# SAM9X75D2GN4 device description
Architecture: ARM926EJ-S; Family: SAM9; Series: SAM9X7
Registers are 32-bit, read-write, reset 0x0 unless marked. A register's access mark holds for its fields unless they carry their own. Offsets are from the block's base; [hi:lo] are bit positions; lines under a group give offsets from that group; {n}, {i} and the like mark numbered series; 'fields as' and 'values as' point back to an identical list.

## GMAC (part 1 of 3) — Gigabit Ethernet MAC
Instances: GMAC 0xF802C000
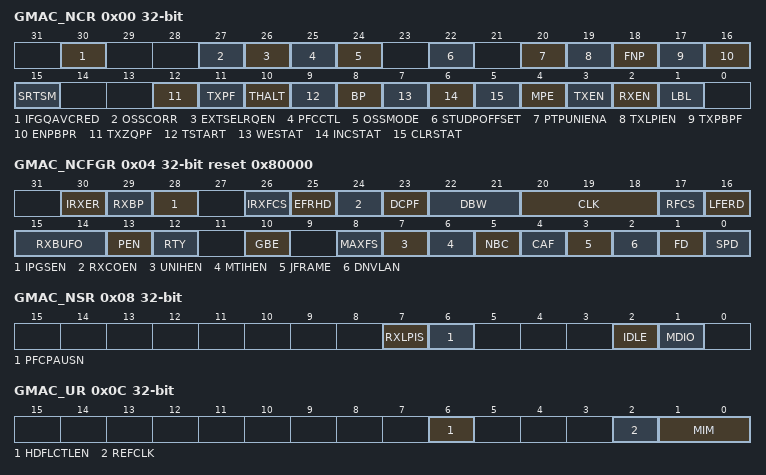
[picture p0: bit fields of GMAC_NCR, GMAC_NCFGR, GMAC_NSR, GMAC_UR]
0x00 GMAC_NCR — Network Control Register
  [30] IFGQAVCRED — Credit-Based Shaping Algorithm Modification
    0=No modification of the CBS algorithm; 1=Modifies the CBS algorithm so the IFG/IPG associated with a transmit frame counts towards its 802.1Qav credit
  [27] OSSCORR — OSS Correction Field
  [26] EXTSELRQEN — External Selection of Receive Queue Enable
    0=Disables external selection of receive queue; 1=Enables external selection of receive queue
  [25] PFCCTL — Multiple PFC Pause quantum Enable
    0=Disables multiple PFC pause quantums; 1=Enables multiple PFC pause quantums, one per pause priority
  [24] OSSMODE — One Step Sync Mode
    0=1588 One Step Sync Mode is disabled; 1=1588 One Step Sync Mode is enabled. Replaces timestamp field in the 1588 header for TX Sync Frames with the current TSU timer value.
  [22] STUDPOFFSET — Store UDP Offset
    0=Normal operations; 1=The upper 16 bits of the CRC of every received frame are replaced with the offset from start of frame to the beginning of the UDP or TCP header. The lower 16 bits of the CRC are replaced with zero and reserved for future use. The offset is measured in units of 2 bytes.
  [20] PTPUNIENA — Detection of Unicast PTP Frames Enable
    0=Disables detection of unicast PTP frames; 1=Enables detection of unicast PTP frames
  [19] TXLPIEN — Enable LPI Transmission
  [18] FNP — Flush Next Packet
    0=No effect; 1=Flushes the next packet from the receive memory. This will only have an effect if the DMA is not currently writing a packet already stored in the receive memory to system memory.
  [17] TXPBPF — Transmit PFC Priority-based Pause Frame
    0=No effect; 1=Takes the values stored in the Transmit PFC Pause Register
  [16] ENPBPR — Enable PFC Priority-based Pause Reception
  [15] SRTSM — Store Receive Timestamp to Memory
    0=No effect; 1=Causes the CRC of every received frame to be replaced with the value of the nanoseconds field of the 1588 timer that was captured as the receive frame passed the message timestamp point. Note that bit RFCS in register GMAC_NCFGR may not be set to 1 when the timer should be captured.
  [12] TXZQPF — Transmit Zero Quantum Pause Frame (Write-only)
    0=No effect; 1=Generates a pause frame with zero quantum to be transmitted
  [11] TXPF — Transmit Pause Frame (Write-only)
    0=No effect; 1=Generates a pause frame to be transmitted
  [10] THALT — Transmit Halt (Write-only)
    0=No effect; 1=Halts transmission as soon as any ongoing frame transmission ends
  [9] TSTART — Start Transmission (Write-only)
    0=No effect; 1=Starts transmission
  [8] BP — Back Pressure
    0=No effect; 1=When the MAC is set in 10M or 100M Half Duplex mode, forces collisions on all received frames. Ignored in Gigabit Half Duplex mode.
  [7] WESTAT — Write Enable for Statistics Registers
    0=Forces the statistics registers to be in read-only mode for normal operation mode; 1=Makes the statistics registers writable for functional test purposes
  [6] INCSTAT — Increment Statistics Registers (Write-only)
  [5] CLRSTAT — Clear Statistics Registers (Write-only)
    0=No effect; 1=Clears the statistics registers
  [4] MPE — Management Port Enable
    0=Forces GMDIO to high impedance state and MDC low; 1=Enables the management port
  [3] TXEN — Transmit Enable
    0=Stops transmission immediately, the transmit pipeline and control registers will be cleared and the Transmit Queue Pointer Register will reset to point to the start of the transmit descriptor list; 1=Enables the GMAC transmitter to send data
  [2] RXEN — Receive Enable
    0=Stops frame reception immediately and the receive pipeline will be cleared. The Receive Queue Pointer register is unaffected.; 1=Enables the GMAC to receive data
  [1] LBL — Loop Back Local
    0=Normal operating mode (no loop back); 1=Connects GTX to GRX, GTXEN to GRXDV and forces Full Duplex mode. GRXCK and GTXCK may malfunction as the GMAC is switched into and out of internal loop back. It is important that receive and transmit circuits have already been disabled when making the switch into and out of internal loop back.
0x04 GMAC_NCFGR reset 0x80000 — Network Configuration Register
  [30] IRXER — Ignore Receive Error from PHY
  [29] RXBP — Receive Bad Preamble
  [28] IPGSEN — IP Stretch Enable
  [26] IRXFCS — Ignore RX FCS
  [25] EFRHD — Enable Frames Received in Half Duplex
  [24] RXCOEN — Receive Checksum Offload Enable
  [23] DCPF — Disable Copy of Pause Frames
  [22:21] DBW — Data Bus Width
  [20:18] CLK — MDC CLock Division
    0=MCK_8 (MCK divided by 8 (MCK up to 20 MHz)); 1=MCK_16 (MCK divided by 16 (MCK up to 40 MHz)); 2=MCK_32 (MCK divided by 32 (MCK up to 80 MHz)); 3=MCK_48 (MCK divided by 48 (MCK up to 120 MHz)); 4=MCK_64 (MCK divided by 64 (MCK up to 160 MHz)); 5=MCK_96 (MCK divided by 96 (MCK up to 240 MHz))
  [17] RFCS — Remove FCS
  [16] LFERD — Length Field Error Frame Discard
  [15:14] RXBUFO — Receive Buffer Offset
  [13] PEN — Pause Enable
  [12] RTY — Retry Test0
  [10] GBE — Gigabit Mode Enable
    0=10/100 operation; 1=Gigabit operation
  [8] MAXFS — 1536 Maximum Frame Size
  [7] UNIHEN — Unicast Hash Enable
  [6] MTIHEN — Multicast Hash Enable
  [5] NBC — No Broadcast
  [4] CAF — Copy All Frames
  [3] JFRAME — Jumbo Frame Size
  [2] DNVLAN — Discard Non-VLAN FRAMES
  [1] FD — Full Duplex
  [0] SPD — Speed
0x08 GMAC_NSR ro reset not defined — Network Status Register
  [7] RXLPIS — LPI Indication
  [6] PFCPAUSN — PFC Pause Negotiated
  [2] IDLE — PHY Management Logic Idle
  [1] MDIO — MDIO Input Status
0x0C GMAC_UR — User Register
  [6] HDFLCTLEN — Half Duplex Flow Control Enable
    0=Half duplex flow control is disabled; 1=Half duplex flow control is enabled
  [2] REFCLK — Source for the GMAC Reference Clock
    0=INTERNAL_GCLK (Selects the GCLK from PMC); 1=EXTERNAL (Selects the clock from an IO)
  [1:0] MIM — Media Interface Mode
    1=RMII (Selects the RMII mode.); 2=RGMII (Selects the RGMII mode.)
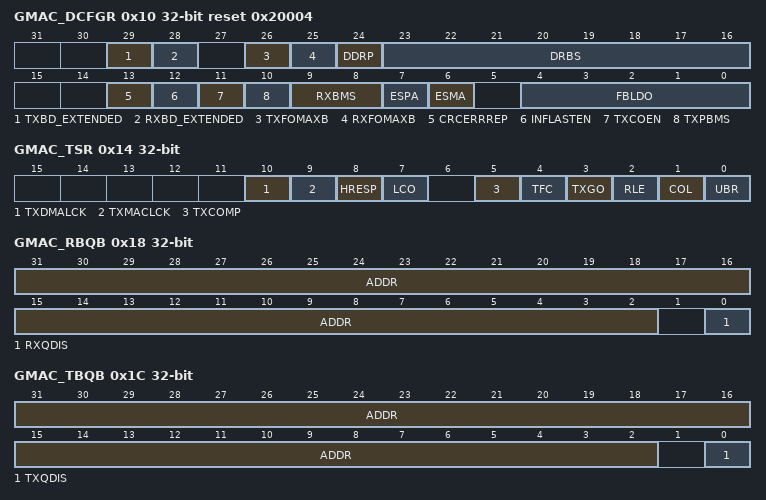
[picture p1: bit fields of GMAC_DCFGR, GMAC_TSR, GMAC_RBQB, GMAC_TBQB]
0x10 GMAC_DCFGR reset 0x20004 — DMA Configuration Register
  [29] TXBD_EXTENDED — Transmit Buffer Descriptor Extended Mode
    0=Disables Transmit Buffer Data Extended mode; 1=Enables Transmit Buffer Data Extended mode
  [28] RXBD_EXTENDED — Receive Buffer Descriptor Extended Mode
    0=Disables Receive Buffer Data Extended mode; 1=Enables Receive Buffer Data Extended mode
  [26] TXFOMAXB — Force Transmit Max Burst Length
  [25] RXFOMAXB — Force Receive Max Burst Length
  [24] DDRP — DMA Discard Receive Packets
  [23:16] DRBS — DMA Receive Buffer Size
    2=128 bytes; 24=1536 bytes (1 x max length frame/buffer); 160=10240 bytes (1 x 10K jumbo frame/buffer)
  [13] CRCERRREP — CRC Errors Report
    0=Bit 16 of the receive buffer descriptor represents the Canonical format indicator (CFI) bit as extracted from the receive frame (if the receive buffer descriptor is pointing to the last data buffer of the receive frame and the received frame was VLAN tagged); 1=Bit 16 of the receive buffer descriptor represents the FCS/CRC error (only if frames with FCS are copied to memory as enabled by bit 26 in the Network Configuration register)
  [12] INFLASTEN — Infinite Size for Last Buffer Enable
  [11] TXCOEN — Transmitter Checksum Generation Offload Enable
  [10] TXPBMS — Transmitter Packet Buffer Memory Size Select
    0=TWO_KB (Do not use top address bit (2 Kbytes).); 1=FOUR_KB (Use full configured addressable space (4 Kbytes).)
  [9:8] RXBMS — Receiver Packet Buffer Memory Size Select
    0=EIGHTH (4/8 Kbyte Memory Size); 1=QUARTER (4/4 Kbytes Memory Size); 2=HALF (4/2 Kbytes Memory Size); 3=FULL (4 Kbytes Memory Size)
  [7] ESPA — Endian Swap Mode Enable for Packet Data Accesses
    0=LITTLE_ENDIAN (Selects Little-endian endianism for system bus transfers.); 1=BIG_ENDIAN (Selects swapped endianism for system bus transfers.)
  [6] ESMA — Endian Swap Mode Enable for Management Descriptor Accesses
    values as ESPA
  [4:0] FBLDO — Fixed Burst Length for DMA Data Operations:
    1=SINGLE (Always use single access on system bus); 4=INCR4 (Attempt to use 4-beat bursts on system bus (Default)); 8=INCR8 (Attempt to use 8-beat bursts on system bus bursts); 16=INCR16 (Attempt to use 16-beat bursts on system bus bursts)
0x14 GMAC_TSR — Transmit Status Register
  [10] TXDMALCK — Transmit DMA Lockup (Clear by Writing a 1)
  [9] TXMACLCK — Transmit MAC Lockup (Clear by Writing a 1)
  [8] HRESP — System Bus Response
  [7] LCO — Late Collision Occurred
  [5] TXCOMP — Transmit Complete
  [4] TFC — Transmit Frame Corruption Due to System Bus Error
  [3] TXGO — Transmit Go (Read only)
  [2] RLE — Retry Limit Exceeded
  [1] COL — Collision Occurred
  [0] UBR — Used Bit Read
0x18 GMAC_RBQB — Receive Buffer Queue Base Address Register
  [31:2] ADDR — Receive Buffer Queue Base Address
  [0] RXQDIS — Receive Queue Disable
    0=Queue is enabled; 1=Queue is disabled. Used to reduce the number of active queues and should only be changed while receive is not enabled.
0x1C GMAC_TBQB — Transmit Buffer Queue Base Address Register
  [31:2] ADDR — Transmit Buffer Queue Base Address
  [0] TXQDIS — Transmit Queue Disable
    0=Queue is enabled; 1=Queue is disabled. Used to reduce the number of active queues and should only be changed while transmit is not enabled.
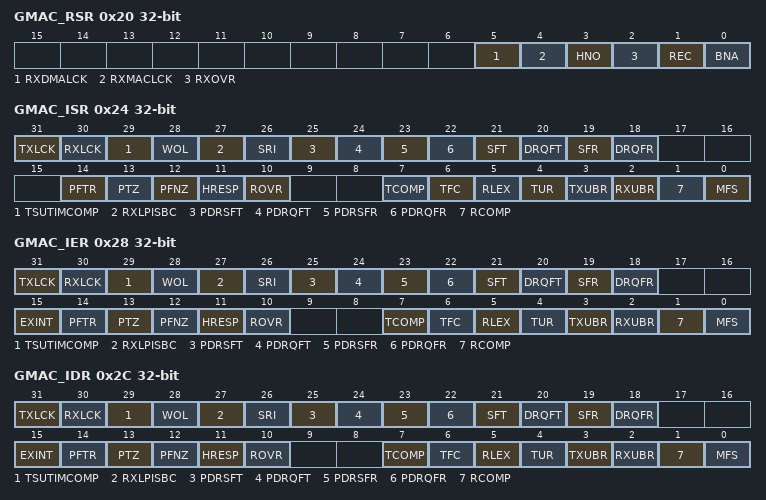
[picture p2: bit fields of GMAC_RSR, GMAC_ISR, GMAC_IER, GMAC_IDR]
0x20 GMAC_RSR — Receive Status Register
  [5] RXDMALCK — Receive DMA Lockup (Clear by Writing a 1)
  [4] RXMACLCK — Receive MAC Lockup (Clear by Writing a 1)
  [3] HNO — System Bus Error
  [2] RXOVR — Receive Overrun
  [1] REC — Frame Received
  [0] BNA — Buffer Not Available
0x24 GMAC_ISR ro — Interrupt Status Register
  [31] TXLCK — Transmit Path Lockup Detected
  [30] RXLCK — Receive Path Lockup Detected
  [29] TSUTIMCOMP — TSU Timer Comparison (Cleared on read)
  [28] WOL — Wake On LAN
  [27] RXLPISBC — Receive LPI indication Status Bit Change (Cleared on read)
  [26] SRI — TSU Seconds Register Increment (Cleared on read)
  [25] PDRSFT — PDelay Response Frame Transmitted (Cleared on read)
  [24] PDRQFT — PDelay Request Frame Transmitted (Cleared on read)
  [23] PDRSFR — PDelay Response Frame Received (Cleared on read)
  [22] PDRQFR — PDelay Request Frame Received (Cleared on read)
  [21] SFT — PTP Sync Frame Transmitted (Cleared on read)
  [20] DRQFT — PTP Delay Request Frame Transmitted (Cleared on read)
  [19] SFR — PTP Sync Frame Received (Cleared on read)
  [18] DRQFR — PTP Delay Request Frame Received (Cleared on read)
  [14] PFTR — Pause Frame Transmitted (Cleared on read)
  [13] PTZ — Pause Time Zero (Cleared on read)
  [12] PFNZ — Pause Frame with Non-zero Pause Quantum Received (Cleared on read)
  [11] HRESP — System Bus Error (Cleared on read)
  [10] ROVR — Receive Overrun (Cleared on read)
  [7] TCOMP — Transmit Complete (Cleared on read)
  [6] TFC — Transmit Frame Corruption Due to System Bus Error (Cleared on read)
  [5] RLEX — Retry Limit Exceeded or Late Collision (Cleared on read)
  [4] TUR — Transmit Underrun (Cleared on read)
  [3] TXUBR — TX Used Bit Read (Cleared on read)
  [2] RXUBR — RX Used Bit Read (Cleared on read)
  [1] RCOMP — Receive Complete (Cleared on read)
  [0] MFS — Management Frame Sent (Cleared on read)
0x28 GMAC_IER wo reset not defined (atomic set of GMAC_IMR) — Interrupt Enable Register
  [31] TXLCK — Transmit Path Lockup Detected
  [30] RXLCK — Receive Path Lockup Detected
  [29] TSUTIMCOMP — TSU Timer Comparison
  [28] WOL — Wake On LAN
  [27] RXLPISBC — Enable RX LPI Indication
  [26] SRI — TSU Seconds Register Increment
  [25] PDRSFT — PDelay Response Frame Transmitted
  [24] PDRQFT — PDelay Request Frame Transmitted
  [23] PDRSFR — PDelay Response Frame Received
  [22] PDRQFR — PDelay Request Frame Received
  [21] SFT — PTP Sync Frame Transmitted
  [20] DRQFT — PTP Delay Request Frame Transmitted
  [19] SFR — PTP Sync Frame Received
  [18] DRQFR — PTP Delay Request Frame Received
  [15] EXINT — External Interrupt
  [14] PFTR — Pause Frame Transmitted
  [13] PTZ — Pause Time Zero
  [12] PFNZ — Pause Frame with Non-zero Pause Quantum Received
  [11] HRESP — System Bus Error
  [10] ROVR — Receive Overrun
  [7] TCOMP — Transmit Complete
  [6] TFC — Transmit Frame Corruption Due to System Bus Error
  [5] RLEX — Retry Limit Exceeded or Late Collision
  [4] TUR — Transmit Underrun
  [3] TXUBR — TX Used Bit Read
  [2] RXUBR — RX Used Bit Read
  [1] RCOMP — Receive Complete
  [0] MFS — Management Frame Sent
0x2C GMAC_IDR wo reset not defined (atomic clear of GMAC_IMR) — Interrupt Disable Register
  fields as GMAC_IER
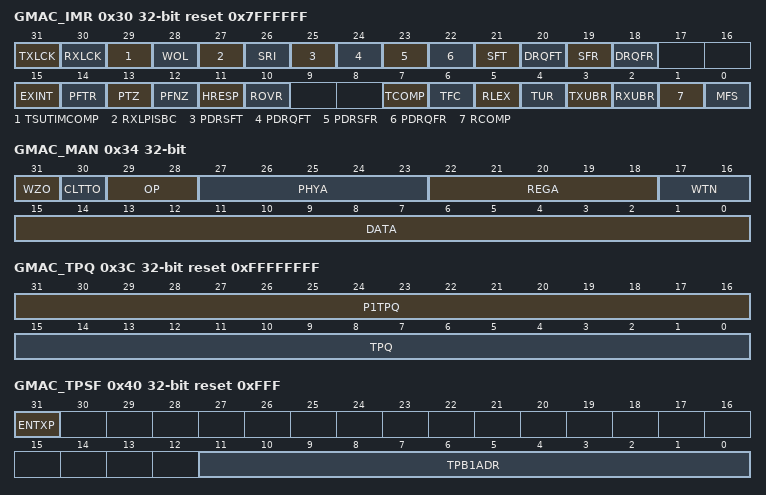
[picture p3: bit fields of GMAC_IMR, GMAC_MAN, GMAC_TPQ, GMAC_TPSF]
0x30 GMAC_IMR reset 0x7FFFFFF — Interrupt Mask Register
  fields as GMAC_IER
0x34 GMAC_MAN — PHY Maintenance Register
  [31] WZO — Write ZERO
  [30] CLTTO — Clause 22 Operation
    0=Clause 45 operation; 1=Clause 22 operation
  [29:28] OP — Operation
    1=Write; 2=Read
  [27:23] PHYA — PHY Address
  [22:18] REGA — Register Address
  [17:16] WTN — Write Ten
  [15:0] DATA — PHY Data
0x38 GMAC_RPQ ro — Receive Pause Quantum Register
  [15:0] RPQ — Received Pause Quantum
0x3C GMAC_TPQ reset 0xFFFFFFFF — Transmit Pause Quantum Register
  [31:16] P1TPQ — Priority 1 Transmit Pause Quantum
  [15:0] TPQ — Transmit Pause Quantum
0x40 GMAC_TPSF reset 0xFFF — TX Partial Store and Forward Register
  [31] ENTXP — Enable TX Partial Store and Forward Operation
  [11:0] TPB1ADR — Transmit Partial Store and Forward Address
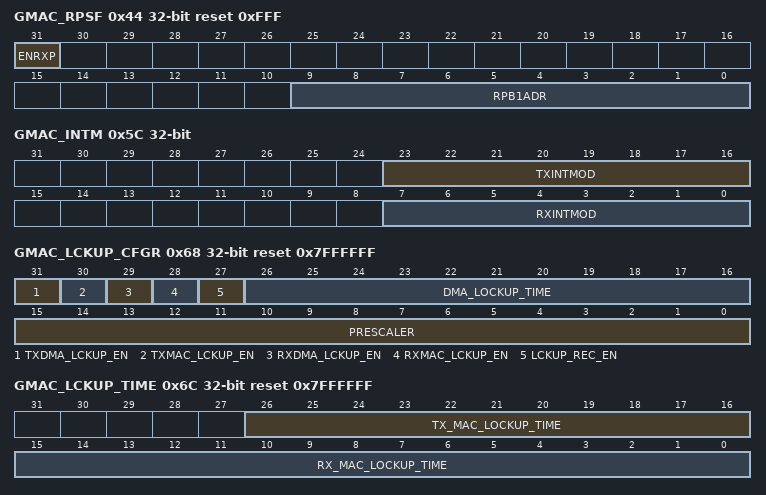
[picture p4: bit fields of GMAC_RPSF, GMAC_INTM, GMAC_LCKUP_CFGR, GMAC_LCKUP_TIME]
0x44 GMAC_RPSF reset 0xFFF — RX Partial Store and Forward Register
  [31] ENRXP — Enable RX Partial Store and Forward Operation
  [9:0] RPB1ADR — Receive Partial Store and Forward Address
0x48 GMAC_RJFML reset 0x2800 — RX Jumbo Frame Max Length Register
  [13:0] FML — Frame Max Length
0x5C GMAC_INTM — Interrupt Moderation Register
  [23:16] TXINTMOD — Transmit Interrupt Moderation
  [7:0] RXINTMOD — Receive Interrupt Moderation
0x60 GMAC_SYSWT — System Wake-Up Time Register
  [15:0] SYSWKUPTIME — System Wake-up Time
0x68 GMAC_LCKUP_CFGR reset 0x7FFFFFF — Lockup Configuration Register
  [31] TXDMA_LCKUP_EN — Transmit DMA Lockup Detector Enable
    0=Disables the monitor that detects lockups in the transmit DMA; 1=Enables the monitor that detects lockups in the transmit DMA
  [30] TXMAC_LCKUP_EN — Transmit MAC Lockup Detector Enable
    0=Disables the monitor that detects lockups in the transmit MAC; 1=Enables the monitor that detects lockups in the transmit MAC
  [29] RXDMA_LCKUP_EN — Receive DMA Lockup Detector Enable
    0=Disables the monitor that detects lockups in the receive DMA; 1=Enables the monitor that detects lockups in the receive DMA
  [28] RXMAC_LCKUP_EN — Receive MAC Lockup Detector Enable
    0=Disables the monitor that detects lockups in the receive MAC; 1=Enables the monitor that detects lockups in the receive MAC
  [27] LCKUP_REC_EN — Lockup RecoveryEnable
    0=No effect; 1=Forces the MAC in Reset mode when a lockup.is detected on the transmit or receive data paths
  [26:16] DMA_LOCKUP_TIME — Timeout Value for Receive and Transmit DMA
  [15:0] PRESCALER — Prescaler Value for Timeout
0x6C GMAC_LCKUP_TIME reset 0x7FFFFFF — MAC Lockup Detection Time register
  [26:16] TX_MAC_LOCKUP_TIME — Transmit MAC Lockup Detector Time
  [15:0] RX_MAC_LOCKUP_TIME — Receive MAC Lockup Detector Time
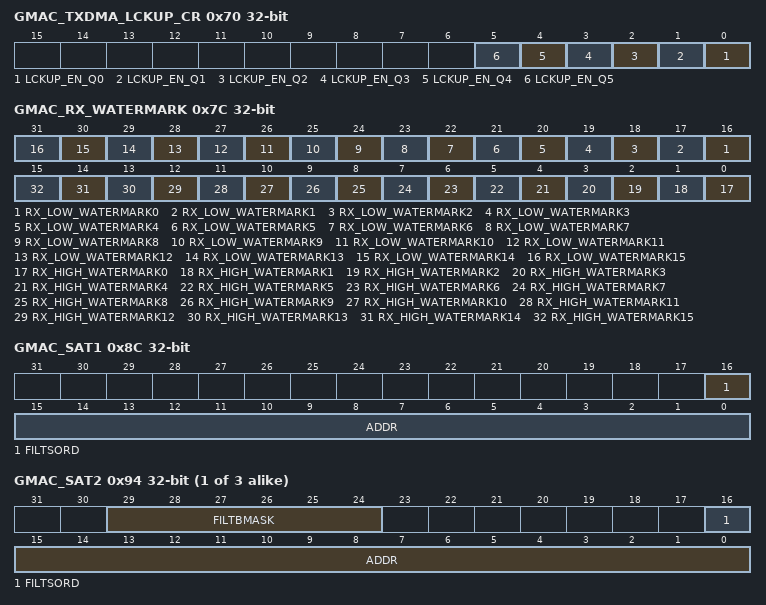
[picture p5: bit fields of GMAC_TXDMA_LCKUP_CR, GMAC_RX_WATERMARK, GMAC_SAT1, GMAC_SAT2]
0x70 GMAC_TXDMA_LCKUP_CR — Transmit DMA Lockup Control Register
  [all] fields
    0=Disables the transmit DMA lockup timer for queue x. The number of outstanding packets are still counted but the actual timer does not run.; 1=Enables the transmit DMA lockup timer for queue x
  [n] LCKUP_EN_Q{n} (n=0..5) — Transmit DMA Lockup Detector Enable for Queue {n}
0x7C GMAC_RX_WATERMARK — Receive Watermark Register
  [n+16] RX_LOW_WATERMARK{n} (n=0..15) — Transmit DMA Lockup Detector Enable for Queue {n}
  [n] RX_HIGH_WATERMARK{n} (n=0..15) — Transmit DMA Lockup Detector Enable for Queue {n}
0x80 GMAC_HRB — Hash Register Bottom
  [31:0] ADDR — Hash Address
0x84 GMAC_HRT — Hash Register Top
  [31:0] ADDR — Hash Address
{0x80+8i} GMAC_SAB{i} (i=1..4) — Specific Address {i} Bottom Register
  [31:0] ADDR — Specific Address {i}
0x8C GMAC_SAT1 — Specific Address 1 Top Register
  [16] FILTSORD — Filter Source or Destination MAC Address
    0=The filter is a destination address filter; 1=The filter is a source address filter
  [15:0] ADDR — Specific Address 1
{0x84+8i} GMAC_SAT{i} (i=2..4) — Specific Address {i} Top Register
  [29:24] FILTBMASK — Filter Bytes Mask
    1=BIT1 (Controls whether the first byte has been received.); 2=BIT2 (Controls whether the second byte has been received.); 4=BIT3 (Controls whether the third byte has been received.); 8=BIT4 (Controls whether the fourth byte has been received.); 16=BIT5 (Controls whether the fifth byte has been received.); 32=BIT6 (Controls whether the sixth byte has been received)
  [16] FILTSORD — Filter Source or Destination MAC Address
    values as GMAC_SAT1.FILTSORD
  [15:0] ADDR — Specific Address {i}
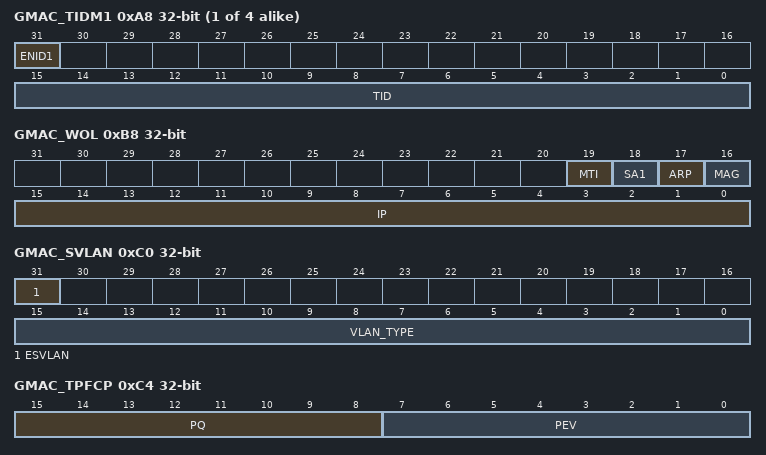
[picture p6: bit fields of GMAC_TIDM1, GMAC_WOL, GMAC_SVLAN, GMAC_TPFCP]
{0xA4+4i} GMAC_TIDM{i} (i=1..4) — Type ID Match {i} Register
  [31] ENID{i} — Enable Copying of TID Matched Frames
    0=TID is not part of the comparison match; 1=TID is processed for the comparison match
  [15:0] TID — Type ID Match {i}
0xB8 GMAC_WOL — Wake on LAN Register
  [19] MTI — Multicast Hash Event Enable
  [18] SA1 — Specific Address Register 1 Event Enable
  [17] ARP — ARP Request Event Enable
  [16] MAG — Magic Packet Event Enable
  [15:0] IP — ARP Request IP Address
0xBC GMAC_IPGS — IPG Stretch Register
  [15:0] FL — Frame Length
0xC0 GMAC_SVLAN — Stacked VLAN Register
  [31] ESVLAN — Enable Stacked VLAN Processing Mode
    0=Disable the stacked VLAN Processing mode; 1=Enable the stacked VLAN Processing mode
  [15:0] VLAN_TYPE — User Defined VLAN_TYPE Field
0xC4 GMAC_TPFCP — Transmit PFC Pause Register
  [15:8] PQ — Pause Quantum
  [7:0] PEV — Priority Enable Vector
0xC8 GMAC_SAMB1 — Specific Address 1 Mask Bottom Register
  [31:0] ADDR — Specific Address 1 Mask
0xCC GMAC_SAMT1 — Specific Address 1 Mask Top Register
  [15:0] ADDR — Specific Address 1 Mask
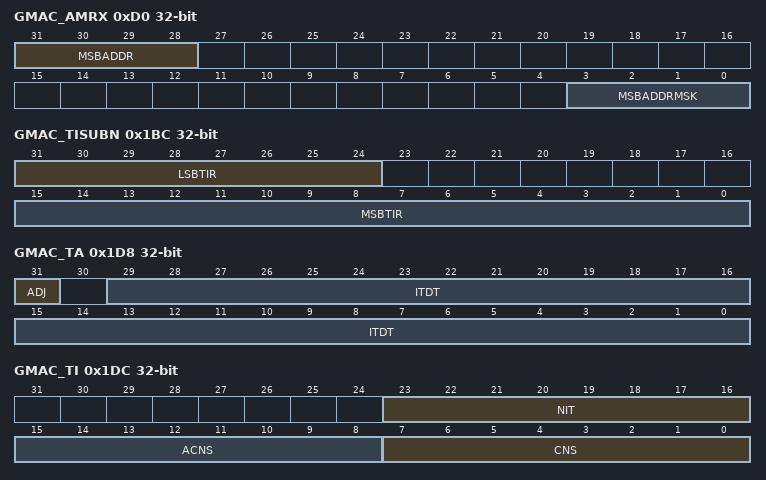
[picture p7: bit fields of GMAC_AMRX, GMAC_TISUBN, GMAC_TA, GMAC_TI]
0xD0 GMAC_AMRX — System Memory Address Mask for RX Data Buffer Accesses Register
  [31:28] MSBADDR — MSB of the Receive Data Buffer Address
  [3:0] MSBADDRMSK — Mask of the Receive Data Buffer Address
0xD4 GMAC_RXUDAR — PTP RX Unicast IP Destination Address Register
  [31:0] RXUDA — Receive Unicast Destination Address
0xD8 GMAC_TXUDAR — PTP TX Unicast IP Destination Address Register
  [31:0] TXUDA — Transmit Unicast Destination Address
0xDC GMAC_NSC — 1588 Timer Nanosecond Comparison Register
  [21:0] NANOSEC — 1588 Timer Nanosecond Comparison Value
0xE0 GMAC_SCL — 1588 Timer Second Comparison Low Register
  [31:0] SEC — 1588 Timer Second Comparison Value
0xE4 GMAC_SCH — 1588 Timer Second Comparison High Register
  [15:0] SEC — 1588 Timer Second Comparison Value
0xE8 GMAC_EFTSH ro — PTP Event Frame Transmitted Seconds High Register
  [15:0] RUD — Register Update
0xEC GMAC_EFRSH ro — PTP Event Frame Received Seconds High Register
  [15:0] RUD — Register Update
0xF0 GMAC_PEFTSH ro — PTP Peer Event Frame Transmitted Seconds High Register
  [15:0] RUD — Register Update
0xF4 GMAC_PEFRSH ro — PTP Peer Event Frame Received Seconds High Register
  [15:0] RUD — Register Update
0x100 GMAC_OTLO ro — Octets Transmitted Low Register
  [31:0] TXO — Transmitted Octets
0x104 GMAC_OTHI ro — Octets Transmitted High Register
  [15:0] TXO — Transmitted Octets
0x108 GMAC_FT ro — Frames Transmitted Register
  [31:0] FTX — Frames Transmitted without Error
0x10C GMAC_BCFT ro — Broadcast Frames Transmitted Register
  [31:0] BFTX — Broadcast Frames Transmitted without Error
0x110 GMAC_MFT ro — Multicast Frames Transmitted Register
  [31:0] MFTX — Multicast Frames Transmitted without Error
0x114 GMAC_PFT ro — Pause Frames Transmitted Register
  [15:0] PFTX
0x118 GMAC_BFT64 ro — 64 Byte Frames Transmitted Register
  [31:0] NFTX — 64 Byte Frames Transmitted without Error
0x11C GMAC_TBFT127 ro — 65 to 127 Byte Frames Transmitted Register
  [31:0] NFTX — 65 to 127 Byte Frames Transmitted without Error
0x120 GMAC_TBFT255 ro — 128 to 255 Byte Frames Transmitted Register
  [31:0] NFTX — 128 to 255 Byte Frames Transmitted without Error
0x124 GMAC_TBFT511 ro — 256 to 511 Byte Frames Transmitted Register
  [31:0] NFTX — 256 to 511 Byte Frames Transmitted without Error
0x128 GMAC_TBFT1023 ro — 512 to 1023 Byte Frames Transmitted Register
  [31:0] NFTX — 512 to 1023 Byte Frames Transmitted without Error
0x12C GMAC_TBFT1518 ro — 1024 to 1518 Byte Frames Transmitted Register
  [31:0] NFTX — 1024 to 1518 Byte Frames Transmitted without Error
0x130 GMAC_GTBFT1518 ro — Greater Than 1518 Byte Frames Transmitted Register
  [31:0] NFTX — Greater than 1518 Byte Frames Transmitted without Error
0x134 GMAC_TUR ro — Transmit Underruns Register
  [9:0] TXUNR — Transmit Underruns
0x138 GMAC_SCF ro — Single Collision Frames Register
  [17:0] SCOL — Single Collision
0x13C GMAC_MCF ro — Multiple Collision Frames Register
  [17:0] MCOL — Multiple Collision
0x140 GMAC_EC ro — Excessive Collisions Register
  [9:0] XCOL — Excessive Collisions
0x144 GMAC_LC ro — Late Collisions Register
  [9:0] LCOL — Late Collisions
0x148 GMAC_DTF ro — Deferred Transmission Frames Register
  [17:0] DEFT — Deferred Transmission
0x14C GMAC_CSE ro — Carrier Sense Errors Register
  [9:0] CSR — Carrier Sense Error
0x150 GMAC_ORLO ro — Octets Received Low Received Register
  [31:0] RXO — Received Octets
0x154 GMAC_ORHI ro — Octets Received High Received Register
  [15:0] RXO — Received Octets
0x158 GMAC_FR ro — Frames Received Register
  [31:0] FRX — Frames Received without Error
0x15C GMAC_BCFR ro — Broadcast Frames Received Register
  [31:0] BFRX — Broadcast Frames Received without Error
0x160 GMAC_MFR ro — Multicast Frames Received Register
  [31:0] MFRX — Multicast Frames Received without Error
0x164 GMAC_PFR ro — Pause Frames Received Register
  [15:0] PFRX
0x168 GMAC_BFR64 ro — 64 Byte Frames Received Register
  [31:0] NFRX — 64 Byte Frames Received without Error
0x16C GMAC_TBFR127 ro — 65 to 127 Byte Frames Received Register
  [31:0] NFRX — 65 to 127 Byte Frames Received without Error
0x170 GMAC_TBFR255 ro — 128 to 255 Byte Frames Received Register
  [31:0] NFRX — 128 to 255 Byte Frames Received without Error
0x174 GMAC_TBFR511 ro — 256 to 511 Byte Frames Received Register
  [31:0] NFRX — 256 to 511 Byte Frames Received without Error
0x178 GMAC_TBFR1023 ro — 512 to 1023 Byte Frames Received Register
  [31:0] NFRX — 512 to 1023 Byte Frames Received without Error
0x17C GMAC_TBFR1518 ro — 1024 to 1518 Byte Frames Received Register
  [31:0] NFRX — 1024 to 1518 Byte Frames Received without Error
0x180 GMAC_TMXBFR ro — 1519 to Maximum Byte Frames Received Register
  [31:0] NFRX — 1519 to Maximum Byte Frames Received without Error
0x184 GMAC_UFR ro — Undersize Frames Received Register
  [9:0] UFRX — Undersize Frames Received
0x188 GMAC_OFR ro — Oversize Frames Received Register
  [9:0] OFRX — Oversized Frames Received
0x18C GMAC_JR ro — Jabbers Received Register
  [9:0] JRX — Jabbers Received
0x190 GMAC_FCSE ro — Frame Check Sequence Errors Register
  [9:0] FCKR — Frame Check Sequence Errors
0x194 GMAC_LFFE ro — Length Field Frame Errors Register
  [9:0] LFER — Length Field Frame Errors
0x198 GMAC_RSE ro — Receive Symbol Errors Register
  [9:0] RXSE — Receive Symbol Errors
0x19C GMAC_AE ro — Alignment Errors Register
  [9:0] AER — Alignment Errors
0x1A0 GMAC_RRE ro — Receive Resource Errors Register
  [17:0] RXRER — Receive Resource Errors
0x1A4 GMAC_ROE ro — Receive Overrun Register
  [9:0] RXOVR — Receive Overruns
0x1A8 GMAC_IHCE ro — IP Header Checksum Errors Register
  [7:0] HCKER — IP Header Checksum Errors
0x1AC GMAC_TCE ro — TCP Checksum Errors Register
  [7:0] TCKER — TCP Checksum Errors
0x1B0 GMAC_UCE ro — UDP Checksum Errors Register
  [7:0] UCKER — UDP Checksum Errors
0x1B4 GMAC_FLRXPCR ro — Flushed Received Packets Counter Register
  [15:0] COUNT — Flushed Received Packets Count (cleared on read)
0x1BC GMAC_TISUBN — 1588 Timer Increment Sub-nanoseconds Register
  [31:24] LSBTIR — Lower Significant Bits of Timer Increment Register
  [15:0] MSBTIR — Most Significant Bits of Timer Increment Register
0x1C0 GMAC_TSH — 1588 Timer Seconds High Register
  [15:0] TCS — Timer Count in Seconds
0x1D0 GMAC_TSL — 1588 Timer Seconds Low Register
  [31:0] TCS — Timer Count in Seconds
0x1D4 GMAC_TN — 1588 Timer Nanoseconds Register
  [29:0] TNS — Timer Count in Nanoseconds
0x1D8 GMAC_TA wo reset not defined — 1588 Timer Adjust Register
  [31] ADJ — Adjust 1588 Timer
  [29:0] ITDT — Increment/Decrement
0x1DC GMAC_TI — 1588 Timer Increment Register
  [23:16] NIT — Number of Increments
  [15:8] ACNS — Alternative Count Nanoseconds
  [7:0] CNS — Count Nanoseconds
0x1E0 GMAC_EFTSL ro — PTP Event Frame Transmitted Seconds Low Register
  [31:0] RUD — Register Update
0x1E4 GMAC_EFTN ro — PTP Event Frame Transmitted Nanoseconds Register
  [29:0] RUD — Register Update
0x1E8 GMAC_EFRSL ro — PTP Event Frame Received Seconds Low Register
  [31:0] RUD — Register Update
0x1EC GMAC_EFRN ro — PTP Event Frame Received Nanoseconds Register
  [29:0] RUD — Register Update
0x1F0 GMAC_PEFTSL ro — PTP Peer Event Frame Transmitted Seconds Low Register
  [31:0] RUD — Register Update
0x1F4 GMAC_PEFTN ro — PTP Peer Event Frame Transmitted Nanoseconds Register
  [29:0] RUD — Register Update
0x1F8 GMAC_PEFRSL ro — PTP Peer Event Frame Received Seconds Low Register
  [31:0] RUD — Register Update
0x1FC GMAC_PEFRN ro — PTP Peer Event Frame Received Nanoseconds Register
  [29:0] RUD — Register Update
0x270 GMAC_RXLPI ro — Received LPI Transitions
  [15:0] COUNT — Count of Received LPI transitions (cleared on read)
0x274 GMAC_RXLPITIME ro — Received LPI Time
  [23:0] LPITIME — Time in LPI (cleared on read)
0x278 GMAC_TXLPI ro — Transmit LPI Transitions
  [15:0] COUNT — Count of LPI transitions (cleared on read)
0x27C GMAC_TXLPITIME ro — Transmit LPI Time
  [23:0] LPITIME — Time in LPI (cleared on read)
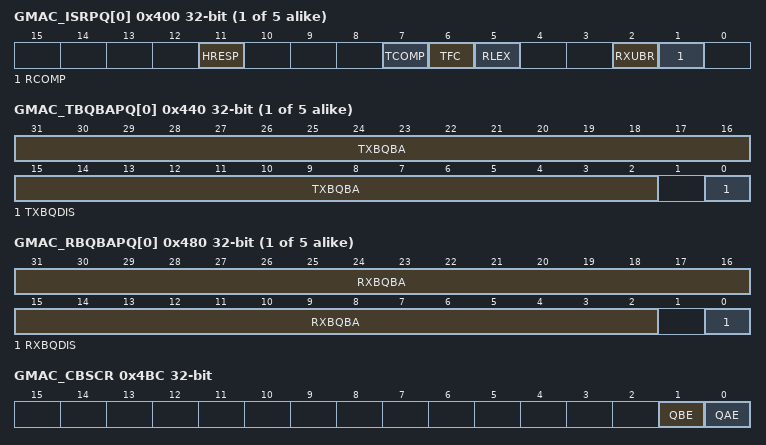
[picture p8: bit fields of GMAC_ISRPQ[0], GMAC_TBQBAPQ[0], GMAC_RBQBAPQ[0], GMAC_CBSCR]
{0x400+4i} GMAC_ISRPQ[{i}] (i=0..4) ro — Interrupt Status Register Priority Queue (index = 1)
  [11] HRESP — System Bus Error
  [7] TCOMP — Transmit Complete
  [6] TFC — Transmit Frame Corruption Due to System Bus Error
  [5] RLEX — Retry Limit Exceeded or Late Collision
  [2] RXUBR — RX Used Bit Read
  [1] RCOMP — Receive Complete
{0x440+4i} GMAC_TBQBAPQ[{i}] (i=0..4) — Transmit Buffer Queue Base Address Register Priority Queue (index = 1)
  [31:2] TXBQBA — Transmit Buffer Queue Base Address
  [0] TXBQDIS — Transmit Buffer Queue Disable
    0=No effect; 1=Disables the transmit queue. This can be used to reduce the number of active queues and must be changed only while transmit is disabled.
{0x480+4i} GMAC_RBQBAPQ[{i}] (i=0..4) — Receive Buffer Queue Base Address Register Priority Queue (index = 1)
  [31:2] RXBQBA — Receive Buffer Queue Base Address
  [0] RXBQDIS — Receive Buffer Queue Disable
    0=No effect; 1=Disables the receive queue. This can be used to reduce the number of active queues and must be changed only while receive is disabled.
{0x4A0+4i} GMAC_RBSRPQ[{i}] (i=0..4) reset 0x2 — Receive Buffer Size Register Priority Queue (index = 1)
  [7:0] RBS — Receive Buffer Size
    values as GMAC_DCFGR.DRBS
0x4BC GMAC_CBSCR — Credit-Based Shaping Control Register
  [1] QBE — Queue B CBS Enable
    0=Credit-based shaping on the highest priority queue (queue B) is disabled; 1=Credit-based shaping on the highest priority queue (queue B) is enabled
  [0] QAE — Queue A CBS Enable
    0=Credit-based shaping on the second highest priority queue (queue A) is disabled; 1=Credit-based shaping on the second highest priority queue (queue A) is enabled
0x4C0 GMAC_CBSISQA — Credit-Based Shaping IdleSlope Register for Queue A
  [31:0] IS — IdleSlope
0x4C4 GMAC_CBSISQB — Credit-Based Shaping IdleSlope Register for Queue B
  [31:0] IS — IdleSlope
0x4C8 GMAC_TQUBA — 32 MSB Transmit Buffer Descriptor Queue Base Address Register
  [31:0] TQUBA — Transmit Queue Upper Buffer Address
0x4CC GMAC_TXBDCTRL — Transmit Buffer Data Control Register
  [5:4] TSMODE — Transmit Descriptor Timestamp Insertion Mode
    0=DISABLE (Timestamp insertion disable.); 1=PTPEVENT (Timestamp inserted for PTP Event Frames only.); 2=PTPALL (Timestamp inserted for All PTP Frames only.); 3=ALL (Timestamp inserted for All Frames.)
0x4D0 GMAC_RXBDCTRL — Receive Buffer Data Control Register
  [5:4] TSMODE — Receive Descriptor Timestamp Insertion Mode
    values as GMAC_TXBDCTRL.TSMODE
0x4D4 GMAC_RQUBA — 32 MSB Receive Buffer Descriptor Queue Base Address Register
  [31:0] RQUBA — Receive Queue Upper Buffer Address
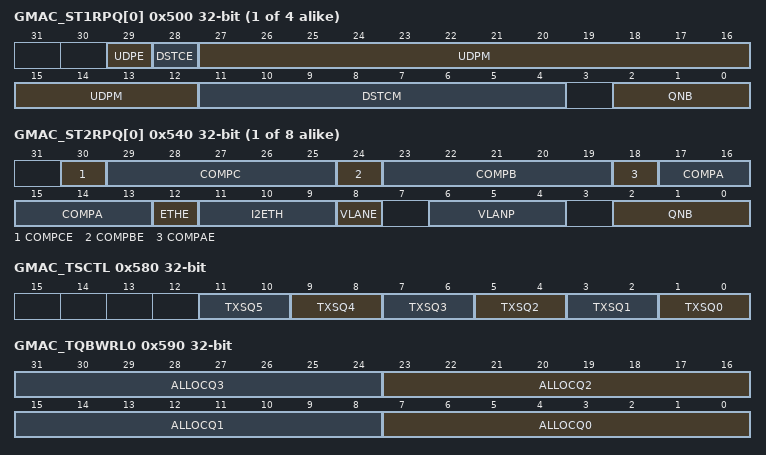
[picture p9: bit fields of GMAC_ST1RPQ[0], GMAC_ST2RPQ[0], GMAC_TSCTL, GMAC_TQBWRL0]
{0x500+4i} GMAC_ST1RPQ[{i}] (i=0..3) — Screening Type 1 Register Priority Queue (index = 0)
  [29] UDPE — UDP Port Match Enable
  [28] DSTCE — Differentiated Services or Traffic Class Match Enable
  [27:12] UDPM — UDP Port Match
  [11:4] DSTCM — Differentiated Services or Traffic Class Match
  [2:0] QNB — Queue Number (0-5)
{0x540+4i} GMAC_ST2RPQ[{i}] (i=0..7) — Screening Type 2 Register Priority Queue (index = 0)
  [30] COMPCE — Compare C Enable
    0=Comparison via the register designated by index COMPC is disabled; 1=Comparison via the register designated by index COMPC is enabled
  [29:25] COMPC — Index of Screening Type 2 Compare Word 0/Word 1 register
  [24] COMPBE — Compare B Enable
    0=Comparison via the register designated by index COMPB is disabled; 1=Comparison via the register designated by index COMPB is enabled
  [23:19] COMPB — Index of Screening Type 2 Compare Word 0/Word 1 register
  [18] COMPAE — Compare A Enable
    0=Comparison via the register designated by index COMPA is disabled; 1=Comparison via the register designated by index COMPA is enabled
  [17:13] COMPA — Index of Screening Type 2 Compare Word 0/Word 1 register
  [12] ETHE — EtherType Enable
    0=EtherType match with bits 15:0 in the register designated by the value of I2ETH is disabled; 1=EtherType match with bits 15:0 in the register designated by the value of I2ETH is enabled
  [11:9] I2ETH — Index of Screening Type 2 EtherType register
  [8] VLANE — VLAN Enable
    0=VLAN match is disabled; 1=VLAN match is enabled
  [6:4] VLANP — VLAN Priority
  [2:0] QNB — Queue Number (0-5)
0x580 GMAC_TSCTL — Transmit Schedule Control Register
  [all] fields
    0=FP (Fixed Priority); 1=CBS (CBS Enabled only valid for top two enabled queues and if CBS capability selected.); 2=DWRR (DWRR enabled); 3=ETS (ETS enabled)
  [2n+1:2n] TXSQ{n} (n=0..5) — Transmit Schedule for Qx
0x590 GMAC_TQBWRL0 — Transmit Queue Bandwidth Rate Limit 0 Register
  [8n+7:8n] ALLOCQ{n} (n=0..3) — DWRR Weighting or ETS Bandwidth Allocation for Qx
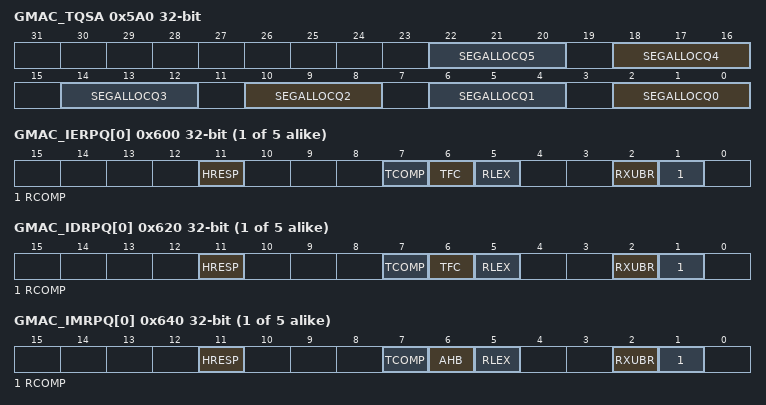
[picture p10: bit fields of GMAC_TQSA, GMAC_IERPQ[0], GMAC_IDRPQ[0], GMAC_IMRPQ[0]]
0x5A0 GMAC_TQSA — Transmit Queue Segment Allocation Register
  [4n+2:4n] SEGALLOCQ{n} (n=0..5) — Segment Allocation for Qx
{0x600+4i} GMAC_IERPQ[{i}] (i=0..4) wo reset not defined (atomic set of GMAC_IMRPQ) — Interrupt Enable Register Priority Queue (index = 1)
  fields as GMAC_ISRPQ[0]
{0x620+4i} GMAC_IDRPQ[{i}] (i=0..4) wo reset not defined (atomic clear of GMAC_IMRPQ) — Interrupt Disable Register Priority Queue (index = 1)
  fields as GMAC_ISRPQ[0]
{0x640+4i} GMAC_IMRPQ[{i}] (i=0..4) — Interrupt Mask Register Priority Queue (index = 1)
  [11] HRESP — System Bus Error
  [7] TCOMP — Transmit Complete
  [6] AHB — Transmit Frame Corruption Due to System Bus Error
  [5] RLEX — Retry Limit Exceeded or Late Collision
  [2] RXUBR — RX Used Bit Read
  [1] RCOMP — Receive Complete
{0x6E0+4i} GMAC_ST2ER[{i}] (i=0..3) — Screening Type 2 Ethertype Register (index = 0)
  [15:0] COMPVAL — Ethertype Compare Value
{0x700+8i} GMAC_ST2CW[{i}] (i=0..23) group
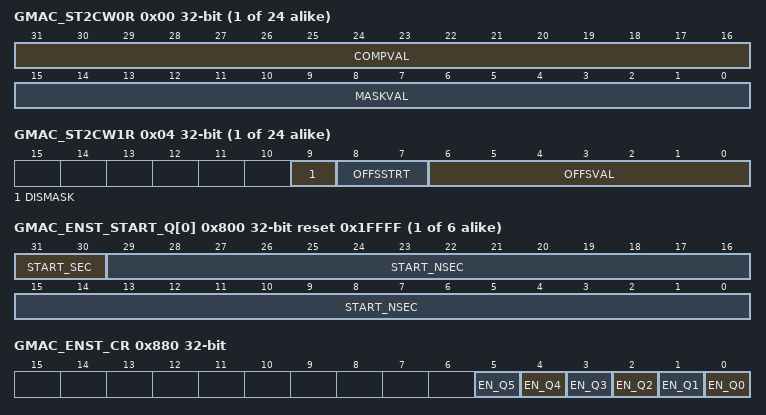
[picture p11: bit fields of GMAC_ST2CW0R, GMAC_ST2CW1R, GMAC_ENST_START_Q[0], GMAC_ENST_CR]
  0x00 GMAC_ST2CW0R — Screening Type 2 Compare Word 0 Register
    [31:16] COMPVAL — Compare Value
    [15:0] MASKVAL — Mask Value
  0x04 GMAC_ST2CW1R — Screening Type 2 Compare Word 1 Register
    [9] DISMASK — Disable Mask
      0=GMAC_ST2CW0R contains a 2-byte compare value with a 2-byte mask value; 1=GMAC_ST2CW0R contains a 4-byte compare value
    [8:7] OFFSSTRT — Ethernet Frame Offset Start
      0=FRAMESTART (Offset from the start of the frame); 1=ETHERTYPE (Offset from the byte after the EtherType field); 2=IP (Offset from the byte after the IP header field); 3=TCP_UDP (Offset from the byte after the TCP/UDP header field)
    [6:0] OFFSVAL — Offset Value in Bytes
{0x800+4i} GMAC_ENST_START_Q[{i}] (i=0..5) reset 0x1FFFF — ENST Start Time Queue Register (index = 0)
  [31:30] START_SEC — Seconds for Start Time
  [29:0] START_NSEC — Nanoseconds for Start Time
{0x820+4i} GMAC_ENST_ON_Q[{i}] (i=0..5) reset 0x1FFFF — ENST On Time Queue Register (index = 0)
  [16:0] ON_TIME — Time for which the Queue is to be Open
{0x840+4i} GMAC_ENST_OFF_Q[{i}] (i=0..5) — ENST Off Time Queue Register (index = 0)
  [16:0] OFF_TIME — Time for which the Queue is to be Blocked
0x880 GMAC_ENST_CR — ENST Control Register
  [all] fields
    0=Disables the enhanced scheduled traffic for queue x; 1=Enables the enhanced scheduled traffic for queue x. EMAC has only 1 queue and ENST is enabled by writing EN_Q0.
  [n] EN_Q{n} (n=0..5) — Enhanced Scheduled Traffic Enable for Queue {n}
0x8A0 GMAC_FRER_TIMEOUT — Frame Elimination Timeout Register
  [15:0] TIMEOUT — Sequence Recovery Timer Restart Period for Credit Based Streams
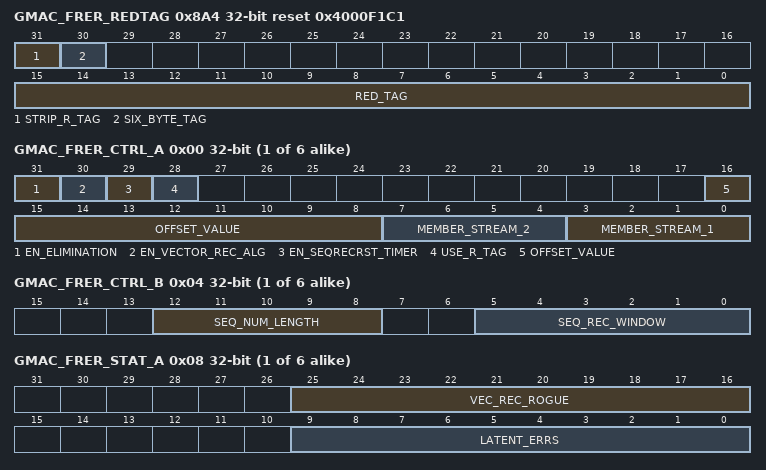
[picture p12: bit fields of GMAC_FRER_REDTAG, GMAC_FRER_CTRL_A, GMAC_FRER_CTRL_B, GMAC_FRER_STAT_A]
0x8A4 GMAC_FRER_REDTAG reset 0x4000F1C1 — Frame Elimination Redundancy Tag Register
  [31] STRIP_R_TAG — Stripping Redundancy Tag Enable
    0=Disables the stripping function. When the statistics counters need to reflect the actual number of octets received, then the stripping functionality must be disabled.; 1=Enables the stripping function, the receive octet counters reflect post deletion frame size so the frame elimination functionality is transparent to higher level management
  [30] SIX_BYTE_TAG — Six-byte Tag Enable
    0=Defines a four-byte tag as per 802.1CB standard revision 2.4 and earlier; 1=Enables the six-byte tag as per 802.1CB standard revision 2.4 and later
  [15:0] RED_TAG — Redundancy Tag (R-TAG)
{0x8C0+0x10*i} GMAC_FRER[{i}] (i=0..5) group
  0x00 GMAC_FRER_CTRL_A — Frame Elimination Control A Register
    [31] EN_ELIMINATION — 802.1CB Elimination of Received Frames Enable
      0=Disables the elimination of received frames; 1=Enables the elimination of received frames
    [30] EN_VECTOR_REC_ALG — 802.1CB Vector Recovery Algorithm Enable
      0=Enables the match recovery algorithm; 1=Enables the vector recovery algorithm
    [29] EN_SEQRECRST_TIMER — 802.1CB Sequence Recovery Reset Timer Enable
      0=Disables the sequence recovery reset timer; 1=Enables the sequence recovery reset timer
    [28] USE_R_TAG — Redundancy Tag Enable
      0=Identifies bottom of sequence number with OFFSET_VALUE; 1=Identifies sequence number with redundancy tag
    [16:8] OFFSET_VALUE — Offset in Bytes from Start Packet Delimiter to MSB for 802.1CB Sequence Number
    [7:4] MEMBER_STREAM_2 — Pointer to Screener Type 2 Register
    [3:0] MEMBER_STREAM_1 — Pointer to Screener Type 2 Register
  0x04 GMAC_FRER_CTRL_B — Frame Elimination Control B Register
    [12:8] SEQ_NUM_LENGTH — Number of Significants bits of the 802.1CB Sequence Number
    [5:0] SEQ_REC_WINDOW — Vector Recovery Window
  0x08 GMAC_FRER_STAT_A ro — Frame Elimination Statistics A Register
    [25:16] VEC_REC_ROGUE — Number of Dropped Frames (Clear on read)
    [9:0] LATENT_ERRS — Number of Sequence Numbers Seen Without a Duplicate (Clear on read)
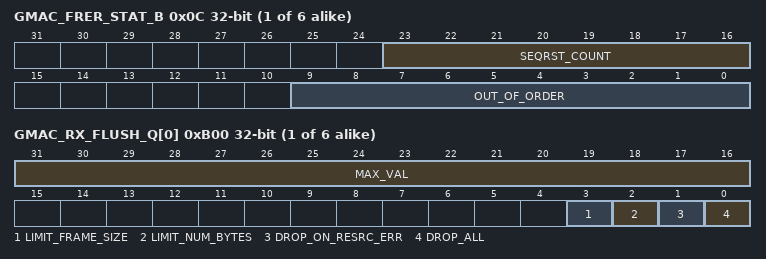
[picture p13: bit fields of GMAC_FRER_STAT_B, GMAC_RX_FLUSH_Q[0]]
  0x0C GMAC_FRER_STAT_B ro — Frame Elimination Statistics B Register
    [23:16] SEQRST_COUNT — Number of Times the Sequence Recovery Reset Timer Decrements to Zero (Clear on read)
    [9:0] OUT_OF_ORDER — Out of Order Sequence Numbers Received (Clear on read)
{0xB00+4i} GMAC_RX_FLUSH_Q[{i}] (i=0..5) — Receive Queue Flush Register (index = 0)
  [31:16] MAX_VAL — Maximum Value for the Received Frame Size or Number of 128-Byte Chunk
  [3] LIMIT_FRAME_SIZE — Maximum Frame-length Received
    0=DISABLED (No effect.); 1=ENABLED (When set, MAX_VAL indicates the maximum frame-length in bytes that may be received. Frames exceeding this length will be dropped. This traffic policing function is relevant to the 802.1Qci standard which specifies stream filtering based on a maximum service data unit (SDU) size.)
  [2] LIMIT_NUM_BYTES — Limitation of the Number of 128-Byte Chunk of Data Stored in the Memory of this Queue
    0=DISABLED (No effect.); 1=ENABLED (Limits the number of 128 byte chunks of data received for this queue and already stored in the memory of the queue awaiting DMA memory writes to the value defined in the field MAX_VAL.)
  [1] DROP_ON_RESRC_ERR — Drop on Resource Error
    0=DISABLED (No effect.); 1=ENABLED (If a free DMA descriptor for this queue cannot be obtained (also referred to as lack of descriptor resource and occurs when the software either cannot free up descriptors quickly enough to meet the receive traffic rate or has deliberately decided not to free any descriptors), all new frames received on this queue will be automatically discarded.)
  [0] DROP_ALL — Drop All Frames
    0=DISABLED (No effect.); 1=ENABLED (Drops all frames of this queue.)

## Notices in the file
Copyright (c) 2024 Microchip Technology Inc.
SPDX-License-Identifier: Apache-2.0
Licensed under the Apache License, Version 2.0 (the "License");
you may not use this file except in compliance with the License.
You may obtain a copy of the License at
http://www.apache.org/licenses/LICENSE-2.0
Unless required by applicable law or agreed to in writing, software
distributed under the License is distributed on an "AS IS" BASIS,
WITHOUT WARRANTIES OR CONDITIONS OF ANY KIND, either express or implied.
See the License for the specific language governing permissions and
limitations under the License.
